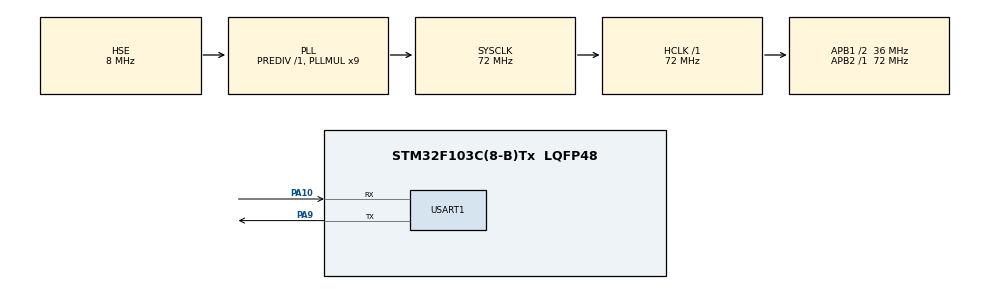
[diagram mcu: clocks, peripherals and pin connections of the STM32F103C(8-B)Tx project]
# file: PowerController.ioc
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Mcu.Family=STM32F1
Mcu.Name=STM32F103C(8-B)Tx
Mcu.Package=LQFP48
NVIC.PriorityGroup=NVIC_PRIORITYGROUP_4
NVIC.TIM1_UP_IRQn=true\:0\:0\:false\:false\:true\:true\:true\:true
NVIC.USART1_IRQn=true\:0\:0\:false\:false\:true\:true\:true\:true
PA10.Mode=Asynchronous
PA10.Signal=USART1_RX
PA13.Mode=Serial_Wire
PA13.Signal=SYS_JTMS-SWDIO
PA14.Mode=Serial_Wire
PA14.Signal=SYS_JTCK-SWCLK
PA9.Mode=Asynchronous
PA9.Signal=USART1_TX
PD0-OSC_IN.Mode=HSE-External-Oscillator
PD0-OSC_IN.Signal=RCC_OSC_IN
PD1-OSC_OUT.Mode=HSE-External-Oscillator
PD1-OSC_OUT.Signal=RCC_OSC_OUT
ProjectManager.HeapSize=0x200
ProjectManager.StackSize=0x400
ProjectManager.TargetToolchain=Makefile
RCC.AHBFreq_Value=72000000
RCC.APB1CLKDivider=RCC_HCLK_DIV2
RCC.APB1Freq_Value=36000000
RCC.APB1TimFreq_Value=72000000
RCC.APB2Freq_Value=72000000
RCC.APB2TimFreq_Value=72000000
RCC.HCLKFreq_Value=72000000
RCC.PLLMUL=RCC_PLL_MUL9
RCC.PLLSourceVirtual=RCC_PLLSOURCE_HSE
RCC.SYSCLKFreq_VALUE=72000000
RCC.SYSCLKSource=RCC_SYSCLKSOURCE_PLLCLK
RCC.USBFreq_Value=72000000
TIM1.CounterMode=TIM_COUNTERMODE_DOWN
TIM1.Period=999
TIM1.Prescaler=7199
TIM1.RepetitionCounter=9
USART1.VirtualMode=VM_ASYNC
VP_TIM1_VS_ClockSourceINT.Mode=Internal
board=custom

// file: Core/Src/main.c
/* USER CODE BEGIN Header */
/**
  ******************************************************************************
  * @file           : main.c
  * @brief          : Main program body
  ******************************************************************************
  * @attention
  *
  * Copyright (c) 2022 STMicroelectronics.
  * All rights reserved.
  *
  * This software is licensed under terms that can be found in the LICENSE file
  * in the root directory of this software component.
  * If no LICENSE file comes with this software, it is provided AS-IS.
  *
  ******************************************************************************
  */
/* USER CODE END Header */
#include "main.h"
#include "tim.h"
#include "usart.h"
#include "gpio.h"

/* USER CODE BEGIN PTD */
enum system_state
{
  STATE_IDLE = 0,
  STATE_WORK,
  STATE_PAUSE
};
typedef enum system_state system_state_t;
/* USER CODE END PTD */

/* USER CODE BEGIN PV */
char cmd = 0;
system_state_t state = STATE_IDLE;
uint32_t work = 1000;
/* USER CODE END PV */

void SystemClock_Config(void);

/* USER CODE BEGIN 0 */
/**
  * @brief  Period elapsed callback in non blocking mode
  * @param  htim : TIM handle
  * @retval None
  */
void HAL_TIM_PeriodElapsedCallback(TIM_HandleTypeDef *htim)
{
  if (htim->Instance == TIM1)
  {
    if(state == STATE_IDLE)
    {
      state = STATE_WORK;
    }
  }
}
/**
  * @brief  Rx Callback when new data is received on the UART.
  * @param  huart: Uart handle receiving the data.
  * @retval None.
  */
void HAL_UART_RxCpltCallback(UART_HandleTypeDef *huart)
{
  if (huart->Instance == USART1)
  {
    if (cmd > '0' && cmd <= '9')
    {
      // set work time
      work = (uint32_t)(cmd - '0') * 1000 / 2;
      // set run period
      htim1.Instance->ARR = (uint32_t)(cmd - '0') * 1000 - 1; // cmd S
      debug_printf("Set period to %d ms\r\n", htim1.Instance->ARR + 1);
    }
    else if (cmd == 's')
    {
      // start work
      if(state == STATE_PAUSE)
      {
        state = STATE_WORK;
      }
    }
    else if (cmd == 'p')
    {
      // stop work
      if(state == STATE_WORK || state == STATE_IDLE)
      {
        state = STATE_PAUSE;
      }
    }
  }
  HAL_UART_Receive_IT(&huart1, (uint8_t *)&cmd, 1);
}

int8_t do_work(uint32_t w)
{
  debug_printf("Start work for %d ms\r\n", w);
  HAL_Delay(w);
  debug_printf("Work done\r\n");
  return 0;
}
/* USER CODE END 0 */

int main(void)
{
  /* USER CODE BEGIN 1 */
  int8_t result = 0;
  /* USER CODE END 1 */

  /* MCU Configuration--------------------------------------------------------*/

  /* Reset of all peripherals, Initializes the Flash interface and the Systick. */
  HAL_Init();

  /* Configure the system clock */
  SystemClock_Config();

  /* Initialize all configured peripherals */
  MX_GPIO_Init();
  MX_USART1_UART_Init();
  MX_TIM1_Init();

  /* Infinite loop */
  /* USER CODE BEGIN WHILE */
  debug_printf("Power controller test\r\n");
  if(HAL_TIM_Base_Start_IT(&htim1) != HAL_OK)
  {
    debug_printf("Start timer failed\r\n");
    Error_Handler();
  }
  if(HAL_UART_Receive_IT(&huart1, (uint8_t *)&cmd, 1) != HAL_OK)
  {
    debug_printf("Start uart failed\r\n");
    Error_Handler();
  }
  while (1)
  {
    /* USER CODE END WHILE */

    /* USER CODE BEGIN 3 */
    switch (state)
    {
    case STATE_PAUSE:
      debug_printf("[PAUSE] Pause work\r\n");
      /* Stop TIM1 */
      HAL_TIM_Base_Stop_IT(&htim1);

      /*Suspend Tick increment to prevent wakeup by Systick interrupt.
      Otherwise the Systick interrupt will wake up the device within 1ms (HAL time base)*/
      HAL_SuspendTick();
      /* Enable Power Control clock */
      __HAL_RCC_PWR_CLK_ENABLE();
      /* Enter Sleep Mode , wake up is done once User push-button is pressed */
      HAL_PWR_EnterSLEEPMode(PWR_MAINREGULATOR_ON, PWR_SLEEPENTRY_WFI);
      /* Resume Tick interrupt if disabled prior to sleep mode entry*/
      HAL_ResumeTick();
      debug_printf("[PAUSE] Wake up from sleep mode\r\n");
      break;
    case STATE_IDLE:
      debug_printf("[IDLE] Enter sleep mode\r\n");
      /*Suspend Tick increment to prevent wakeup by Systick interrupt.
      Otherwise the Systick interrupt will wake up the device within 1ms (HAL time base)*/
      HAL_SuspendTick();
      /* Enable Power Control clock */
      __HAL_RCC_PWR_CLK_ENABLE();
      /* Enter Sleep Mode , wake up is done once User push-button is pressed */
      HAL_PWR_EnterSLEEPMode(PWR_MAINREGULATOR_ON, PWR_SLEEPENTRY_WFI);
      /* Resume Tick interrupt if disabled prior to sleep mode entry*/
      HAL_ResumeTick();
      debug_printf("[IDLE] Wake up from sleep mode\r\n");
      break;
    case STATE_WORK:
      debug_printf("[WORK] Do work for %d ms\r\n", work);
      result = do_work(work);
      if(result == 0 && state == STATE_WORK) // right
      {
        state = STATE_IDLE;
        HAL_TIM_Base_Start_IT(&htim1);
      }
      break;

    default:
      break;
    }
  }
  /* USER CODE END 3 */
}

void SystemClock_Config(void)
{
  RCC_OscInitTypeDef RCC_OscInitStruct = {0};
  RCC_ClkInitTypeDef RCC_ClkInitStruct = {0};

  /** Initializes the RCC Oscillators according to the specified parameters
  * in the RCC_OscInitTypeDef structure.
  */
  RCC_OscInitStruct.OscillatorType = RCC_OSCILLATORTYPE_HSE;
  RCC_OscInitStruct.HSEState = RCC_HSE_ON;
  RCC_OscInitStruct.HSEPredivValue = RCC_HSE_PREDIV_DIV1;
  RCC_OscInitStruct.HSIState = RCC_HSI_ON;
  RCC_OscInitStruct.PLL.PLLState = RCC_PLL_ON;
  RCC_OscInitStruct.PLL.PLLSource = RCC_PLLSOURCE_HSE;
  RCC_OscInitStruct.PLL.PLLMUL = RCC_PLL_MUL9;
  if (HAL_RCC_OscConfig(&RCC_OscInitStruct) != HAL_OK)
  {
    Error_Handler();
  }

  /** Initializes the CPU, AHB and APB buses clocks
  */
  RCC_ClkInitStruct.ClockType = RCC_CLOCKTYPE_HCLK|RCC_CLOCKTYPE_SYSCLK
                              |RCC_CLOCKTYPE_PCLK1|RCC_CLOCKTYPE_PCLK2;
  RCC_ClkInitStruct.SYSCLKSource = RCC_SYSCLKSOURCE_PLLCLK;
  RCC_ClkInitStruct.AHBCLKDivider = RCC_SYSCLK_DIV1;
  RCC_ClkInitStruct.APB1CLKDivider = RCC_HCLK_DIV2;
  RCC_ClkInitStruct.APB2CLKDivider = RCC_HCLK_DIV1;

  if (HAL_RCC_ClockConfig(&RCC_ClkInitStruct, FLASH_LATENCY_2) != HAL_OK)
  {
    Error_Handler();
  }
}

void Error_Handler(void)
{
  /* USER CODE BEGIN Error_Handler_Debug */
  debug_printf("[Error]\r\n");
  /* User can add his own implementation to report the HAL error return state */
  __disable_irq();
  while (1)
  {
  }
  /* USER CODE END Error_Handler_Debug */
}
